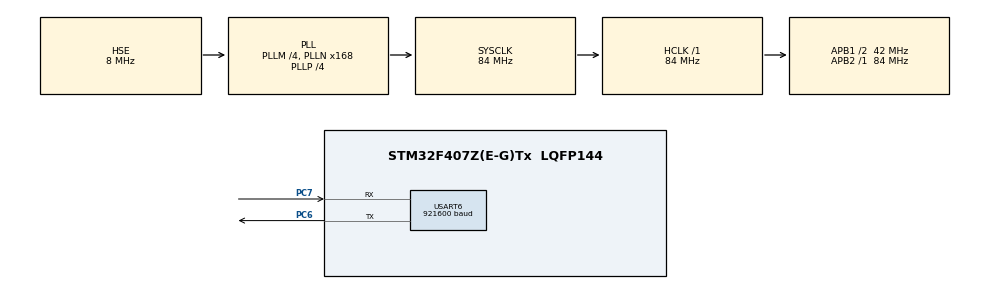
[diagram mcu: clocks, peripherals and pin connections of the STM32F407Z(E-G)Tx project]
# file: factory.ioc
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Dma.Request0=USART6_TX
Dma.Request1=USART6_RX
Dma.USART6_RX.1.Direction=DMA_PERIPH_TO_MEMORY
Dma.USART6_RX.1.FIFOMode=DMA_FIFOMODE_DISABLE
Dma.USART6_RX.1.Instance=DMA2_Stream1
Dma.USART6_RX.1.MemDataAlignment=DMA_MDATAALIGN_BYTE
Dma.USART6_RX.1.MemInc=DMA_MINC_ENABLE
Dma.USART6_RX.1.Mode=DMA_CIRCULAR
Dma.USART6_RX.1.PeriphDataAlignment=DMA_PDATAALIGN_BYTE
Dma.USART6_RX.1.PeriphInc=DMA_PINC_DISABLE
Dma.USART6_RX.1.Priority=DMA_PRIORITY_VERY_HIGH
Dma.USART6_TX.0.Direction=DMA_MEMORY_TO_PERIPH
Dma.USART6_TX.0.FIFOMode=DMA_FIFOMODE_DISABLE
Dma.USART6_TX.0.Instance=DMA2_Stream7
Dma.USART6_TX.0.MemDataAlignment=DMA_MDATAALIGN_BYTE
Dma.USART6_TX.0.MemInc=DMA_MINC_ENABLE
Dma.USART6_TX.0.Mode=DMA_NORMAL
Dma.USART6_TX.0.PeriphDataAlignment=DMA_PDATAALIGN_BYTE
Dma.USART6_TX.0.PeriphInc=DMA_PINC_DISABLE
Dma.USART6_TX.0.Priority=DMA_PRIORITY_VERY_HIGH
IWDG.Prescaler=IWDG_PRESCALER_32
Mcu.Family=STM32F4
Mcu.Name=STM32F407Z(E-G)Tx
Mcu.Package=LQFP144
NVIC.DMA2_Stream1_IRQn=true\:3\:0\:true\:false\:true\:false\:true\:true
NVIC.DMA2_Stream7_IRQn=true\:5\:0\:true\:false\:true\:false\:true\:true
NVIC.PriorityGroup=NVIC_PRIORITYGROUP_4
NVIC.USART6_IRQn=true\:4\:0\:true\:false\:true\:true\:true\:true
PA13.Mode=Serial_Wire
PA13.Signal=SYS_JTMS-SWDIO
PA14.Mode=Serial_Wire
PA14.Signal=SYS_JTCK-SWCLK
PC6.Mode=Asynchronous
PC6.Signal=USART6_TX
PC7.Mode=Asynchronous
PC7.Signal=USART6_RX
PH0-OSC_IN.Mode=HSE-External-Oscillator
PH0-OSC_IN.Signal=RCC_OSC_IN
PH1-OSC_OUT.Mode=HSE-External-Oscillator
PH1-OSC_OUT.Signal=RCC_OSC_OUT
ProjectManager.HeapSize=0x400
ProjectManager.StackSize=0x2000
ProjectManager.TargetToolchain=Makefile
RCC.48MHZClocksFreq_Value=84000000
RCC.AHBFreq_Value=84000000
RCC.APB1CLKDivider=RCC_HCLK_DIV2
RCC.APB1Freq_Value=42000000
RCC.APB1TimFreq_Value=84000000
RCC.APB2Freq_Value=84000000
RCC.APB2TimFreq_Value=84000000
RCC.CortexFreq_Value=84000000
RCC.HCLKFreq_Value=84000000
RCC.HSE_VALUE=8000000
RCC.HSI_VALUE=16000000
RCC.LSE_VALUE=32768
RCC.PLLM=4
RCC.PLLN=168
RCC.PLLP=RCC_PLLP_DIV4
RCC.PLLSourceVirtual=RCC_PLLSOURCE_HSE
RCC.SYSCLKFreq_VALUE=84000000
RCC.SYSCLKSource=RCC_SYSCLKSOURCE_PLLCLK
RCC.VCOOutputFreq_Value=336000000
USART6.BaudRate=921600
USART6.VirtualMode=VM_ASYNC
VP_CRC_VS_CRC.Mode=CRC_Activate
VP_IWDG_VS_IWDG.Mode=IWDG_Activate
board=custom

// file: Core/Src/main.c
/* USER CODE BEGIN Header */
/**
  ******************************************************************************
  * @file           : main.c
  * @brief          : Main program body
  ******************************************************************************
  * @attention
  *
  * Copyright (c) 2023 STMicroelectronics.
  * All rights reserved.
  *
  * This software is licensed under terms that can be found in the LICENSE file
  * in the root directory of this software component.
  * If no LICENSE file comes with this software, it is provided AS-IS.
  *
  ******************************************************************************
  */
/* USER CODE END Header */
#include "main.h"
#include "crc.h"
#include "dma.h"
#include "iwdg.h"
#include "usart.h"
#include "gpio.h"

/* USER CODE BEGIN Includes */
#include <stdio.h>
#include "interface.h"
#include "device.h"
/* USER CODE END Includes */

void SystemClock_Config(void);

int main(void)
{
  /* USER CODE BEGIN 1 */
  SCB->VTOR = ADDR_APP_FACTORY;
  /* USER CODE END 1 */

  /* MCU Configuration--------------------------------------------------------*/

  /* Reset of all peripherals, Initializes the Flash interface and the Systick. */
  HAL_Init();

  /* Configure the system clock */
  SystemClock_Config();

  /* Initialize all configured peripherals */
  MX_GPIO_Init();
  MX_DMA_Init();
  MX_USART6_UART_Init();
  MX_CRC_Init();
  MX_IWDG_Init();
  /* USER CODE BEGIN 2 */
  boot_param_check_upgrade();
  frame_parse_register(FRAME_TYPE_BEGIN, iap_update);
  frame_parse_register(FRAME_TYPE_END, iap_update);
  frame_parse_register(FRAME_TYPE_DATA, iap_update);
  frame_parse_register(FRAME_TYPE_DEBUG, print_frame);
  /* USER CODE END 2 */

  /* Infinite loop */
  /* USER CODE BEGIN WHILE */
  while (1)
  {
    uart6_frame_parse();
    /* USER CODE END WHILE */

    /* USER CODE BEGIN 3 */
    LL_IWDG_ReloadCounter(IWDG);
  }
  /* USER CODE END 3 */
}

void SystemClock_Config(void)
{
  RCC_OscInitTypeDef RCC_OscInitStruct = {0};
  RCC_ClkInitTypeDef RCC_ClkInitStruct = {0};

  /** Configure the main internal regulator output voltage
  */
  __HAL_RCC_PWR_CLK_ENABLE();
  __HAL_PWR_VOLTAGESCALING_CONFIG(PWR_REGULATOR_VOLTAGE_SCALE1);

  /** Initializes the RCC Oscillators according to the specified parameters
  * in the RCC_OscInitTypeDef structure.
  */
  RCC_OscInitStruct.OscillatorType = RCC_OSCILLATORTYPE_LSI|RCC_OSCILLATORTYPE_HSE;
  RCC_OscInitStruct.HSEState = RCC_HSE_ON;
  RCC_OscInitStruct.LSIState = RCC_LSI_ON;
  RCC_OscInitStruct.PLL.PLLState = RCC_PLL_ON;
  RCC_OscInitStruct.PLL.PLLSource = RCC_PLLSOURCE_HSE;
  RCC_OscInitStruct.PLL.PLLM = 4;
  RCC_OscInitStruct.PLL.PLLN = 168;
  RCC_OscInitStruct.PLL.PLLP = RCC_PLLP_DIV4;
  RCC_OscInitStruct.PLL.PLLQ = 4;
  if (HAL_RCC_OscConfig(&RCC_OscInitStruct) != HAL_OK)
  {
    Error_Handler();
  }

  /** Initializes the CPU, AHB and APB buses clocks
  */
  RCC_ClkInitStruct.ClockType = RCC_CLOCKTYPE_HCLK|RCC_CLOCKTYPE_SYSCLK
                              |RCC_CLOCKTYPE_PCLK1|RCC_CLOCKTYPE_PCLK2;
  RCC_ClkInitStruct.SYSCLKSource = RCC_SYSCLKSOURCE_PLLCLK;
  RCC_ClkInitStruct.AHBCLKDivider = RCC_SYSCLK_DIV1;
  RCC_ClkInitStruct.APB1CLKDivider = RCC_HCLK_DIV2;
  RCC_ClkInitStruct.APB2CLKDivider = RCC_HCLK_DIV1;

  if (HAL_RCC_ClockConfig(&RCC_ClkInitStruct, FLASH_LATENCY_2) != HAL_OK)
  {
    Error_Handler();
  }
}

void Error_Handler(void)
{
  __disable_irq();
  while (1)
  {
  }
}
